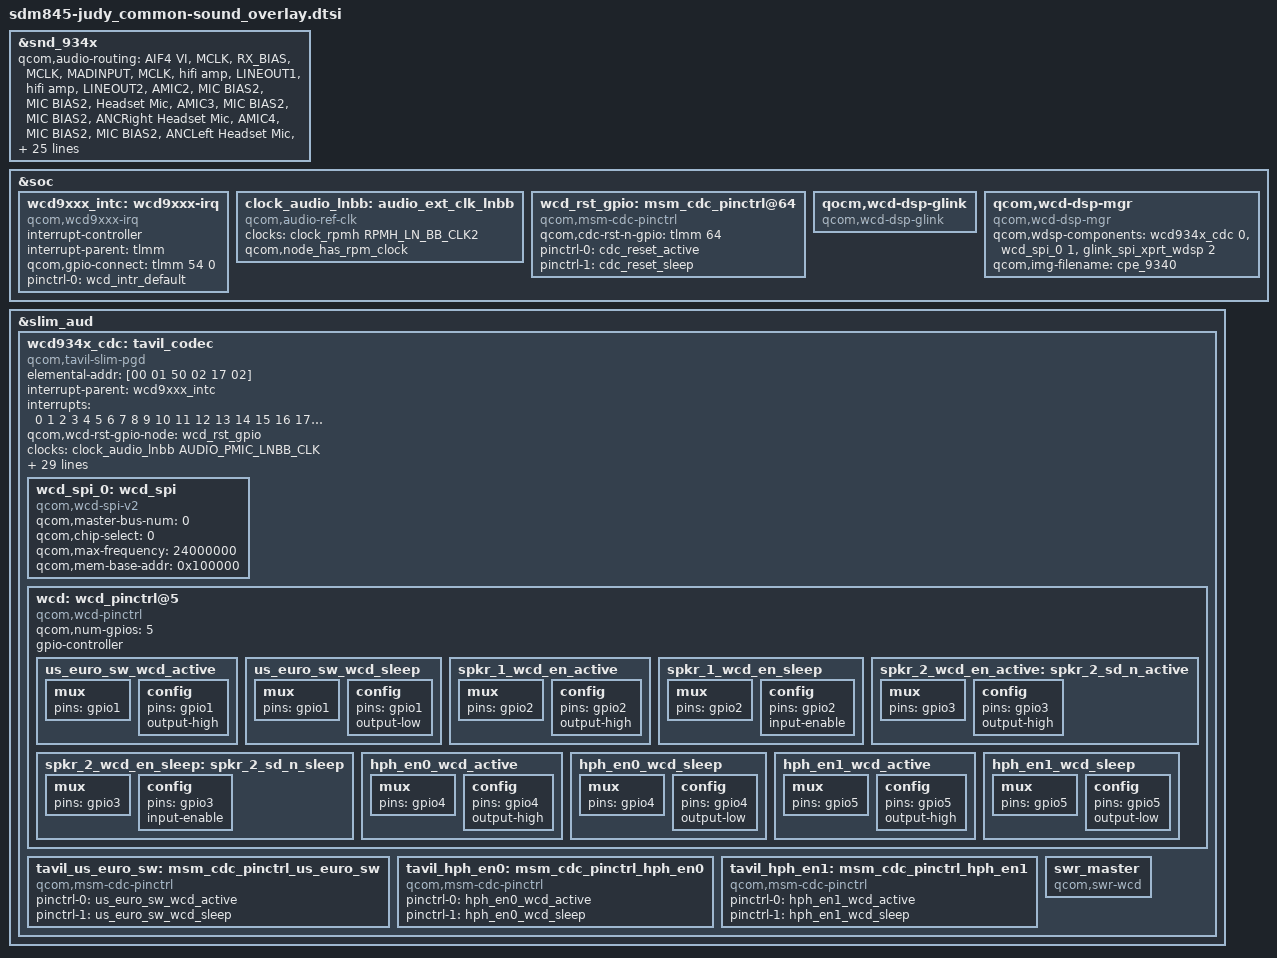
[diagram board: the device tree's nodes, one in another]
/* Copyright (c) 2017, The Linux Foundation. All rights reserved.
 *
 * This program is free software; you can redistribute it and/or modify
 * it under the terms of the GNU General Public License version 2 and
 * only version 2 as published by the Free Software Foundation.
 *
 * This program is distributed in the hope that it will be useful,
 * but WITHOUT ANY WARRANTY; without even the implied warranty of
 * MERCHANTABILITY or FITNESS FOR A PARTICULAR PURPOSE.  See the
 * GNU General Public License for more details.
 */

#include <dt-bindings/clock/qcom,audio-ext-clk.h>

&snd_934x {
	qcom,audio-routing =
		"AIF4 VI", "MCLK",
		"RX_BIAS", "MCLK",
		"MADINPUT", "MCLK",
		"hifi amp", "LINEOUT1",
		"hifi amp", "LINEOUT2",
		"AMIC2", "MIC BIAS2",
		"MIC BIAS2", "Headset Mic",
		"AMIC3", "MIC BIAS2",
		"MIC BIAS2", "ANCRight Headset Mic",
		"AMIC4", "MIC BIAS2",
		"MIC BIAS2", "ANCLeft Headset Mic",
		"AMIC5", "MIC BIAS3",
		"MIC BIAS3", "Handset Mic",
		"DMIC0", "MIC BIAS1",
		"MIC BIAS1", "Digital Mic0",
		"DMIC1", "MIC BIAS1",
		"MIC BIAS1", "Digital Mic1",
		"DMIC2", "MIC BIAS3",
		"MIC BIAS3", "Digital Mic2",
		"DMIC3", "MIC BIAS3",
		"MIC BIAS3", "Digital Mic3",
		"DMIC4", "MIC BIAS4",
		"MIC BIAS4", "Digital Mic4",
		"DMIC5", "MIC BIAS4",
		"MIC BIAS4", "Digital Mic5",
		"SpkrLeft IN", "SPK1 OUT",
		"SpkrRight IN", "SPK2 OUT";

	qcom,msm-mbhc-hphl-swh = <1>;
	qcom,msm-mbhc-gnd-swh = <1>;
	qcom,msm-mbhc-hs-mic-max-threshold-mv = <1700>;
	qcom,msm-mbhc-hs-mic-min-threshold-mv = <50>;
	qcom,hph-en0-gpio = <&tavil_hph_en0>;
	qcom,hph-en1-gpio = <&tavil_hph_en1>;
	qcom,tavil-mclk-clk-freq = <9600000>;

	asoc-codec = <&stub_codec>;
	asoc-codec-names = "msm-stub-codec.1";

	pinctrl-names = "aud_active", "aud_sleep";
	pinctrl-0 = <&wcd_usbc_analog_en2_active>;
	pinctrl-1 = <&wcd_usbc_analog_en2_idle>;

	qcom,wsa-max-devs = <2>;
	qcom,wsa-devs = <&wsa881x_0211>, <&wsa881x_0212>,
			<&wsa881x_0213>, <&wsa881x_0214>;
	qcom,wsa-aux-dev-prefix = "SpkrLeft", "SpkrRight",
				  "SpkrLeft", "SpkrRight";
};

&soc {
/*	wcd_usbc_analog_en1_gpio: msm_cdc_pinctrl@49 {
		compatible = "qcom,msm-cdc-pinctrl";
		pinctrl-names = "aud_active", "aud_sleep";
		pinctrl-0 = <&wcd_usbc_analog_en1_active>;
		pinctrl-1 = <&wcd_usbc_analog_en1_idle>;
	};
*/
	wcd9xxx_intc: wcd9xxx-irq {
		status = "ok";
		compatible = "qcom,wcd9xxx-irq";
		interrupt-controller;
		#interrupt-cells = <1>;
		interrupt-parent = <&tlmm>;
		qcom,gpio-connect = <&tlmm 54 0>;
		pinctrl-names = "default";
		pinctrl-0 = <&wcd_intr_default>;
	};

	clock_audio_lnbb: audio_ext_clk_lnbb {
		status = "ok";
		compatible = "qcom,audio-ref-clk";
		clock-names = "osr_clk";
		clocks = <&clock_rpmh RPMH_LN_BB_CLK2>;
		qcom,node_has_rpm_clock;
		#clock-cells = <1>;
	};

	wcd_rst_gpio: msm_cdc_pinctrl@64 {
		compatible = "qcom,msm-cdc-pinctrl";
		qcom,cdc-rst-n-gpio = <&tlmm 64 0>;
		pinctrl-names = "aud_active", "aud_sleep";
		pinctrl-0 = <&cdc_reset_active>;
		pinctrl-1 = <&cdc_reset_sleep>;
	};

	qocm,wcd-dsp-glink {
		compatible = "qcom,wcd-dsp-glink";
	};

	qcom,wcd-dsp-mgr {
		compatible = "qcom,wcd-dsp-mgr";
		qcom,wdsp-components = <&wcd934x_cdc 0>,
				       <&wcd_spi_0 1>,
				       <&glink_spi_xprt_wdsp 2>;
		qcom,img-filename = "cpe_9340";
	};
};

&slim_aud {
	wcd934x_cdc: tavil_codec {
		compatible = "qcom,tavil-slim-pgd";
		elemental-addr = [00 01 50 02 17 02];

		interrupt-parent = <&wcd9xxx_intc>;
		interrupts = <0 1 2 3 4 5 6 7 8 9 10 11 12 13 14 15 16
			      17 18 19 20 21 22 23 24 25 26 27 28 29
			      30 31>;

		qcom,wcd-rst-gpio-node = <&wcd_rst_gpio>;

		clock-names = "wcd_clk";
		clocks = <&clock_audio_lnbb AUDIO_PMIC_LNBB_CLK>;

		cdc-vdd-buck-supply = <&pm8998_s4>;
		qcom,cdc-vdd-buck-voltage = <1800000 1800000>;
		qcom,cdc-vdd-buck-current = <650000>;

		cdc-buck-sido-supply = <&pm8998_s4>;
		qcom,cdc-buck-sido-voltage = <1800000 1800000>;
		qcom,cdc-buck-sido-current = <250000>;

		cdc-vdd-tx-h-supply = <&pm8998_s4>;
		qcom,cdc-vdd-tx-h-voltage = <1800000 1800000>;
		qcom,cdc-vdd-tx-h-current = <25000>;

		cdc-vdd-rx-h-supply = <&pm8998_s4>;
		qcom,cdc-vdd-rx-h-voltage = <1800000 1800000>;
		qcom,cdc-vdd-rx-h-current = <25000>;

		cdc-vddpx-1-supply = <&pm8998_s4>;
		qcom,cdc-vddpx-1-voltage = <1800000 1800000>;
		qcom,cdc-vddpx-1-current = <10000>;

		qcom,cdc-static-supplies = "cdc-vdd-buck",
					   "cdc-buck-sido",
					   "cdc-vdd-tx-h",
					   "cdc-vdd-rx-h",
					   "cdc-vddpx-1";

		qcom,cdc-micbias1-mv = <1800>;
		qcom,cdc-micbias2-mv = <2100>;
		qcom,cdc-micbias3-mv = <1800>;
		qcom,cdc-micbias4-mv = <1800>;

		qcom,cdc-mclk-clk-rate = <9600000>;
		qcom,cdc-slim-ifd = "tavil-slim-ifd";
		qcom,cdc-slim-ifd-elemental-addr = [00 00 50 02 17 02];
		qcom,cdc-dmic-sample-rate = <4800000>;
		qcom,cdc-mad-dmic-rate = <600000>;

		qcom,wdsp-cmpnt-dev-name = "tavil_codec";

		wcd_spi_0: wcd_spi {
			compatible = "qcom,wcd-spi-v2";
			qcom,master-bus-num = <0>;
			qcom,chip-select = <0>;
			qcom,max-frequency = <24000000>;
			qcom,mem-base-addr = <0x100000>;
		};

	};
};

&slim_aud {
	tavil_codec {
		wcd: wcd_pinctrl@5 {
			compatible = "qcom,wcd-pinctrl";
			qcom,num-gpios = <5>;
			gpio-controller;
			#gpio-cells = <2>;

			us_euro_sw_wcd_active: us_euro_sw_wcd_active {
				mux {
					pins = "gpio1";
				};

				config {
					pins = "gpio1";
					output-high;
				};
			};

			us_euro_sw_wcd_sleep: us_euro_sw_wcd_sleep {
				mux {
					pins = "gpio1";
				};

				config {
					pins = "gpio1";
					output-low;
				};
			};

			spkr_1_wcd_en_active: spkr_1_wcd_en_active {
				mux {
					pins = "gpio2";
				};

				config {
					pins = "gpio2";
					output-high;
				};
			};

			spkr_1_wcd_en_sleep: spkr_1_wcd_en_sleep {
				mux {
					pins = "gpio2";
				};

				config {
					pins = "gpio2";
					input-enable;
				};
			};

			spkr_2_wcd_en_active: spkr_2_sd_n_active {
				mux {
					pins = "gpio3";
				};

				config {
					pins = "gpio3";
					output-high;
				};
			};

			spkr_2_wcd_en_sleep: spkr_2_sd_n_sleep {
				mux {
					pins = "gpio3";
				};

				config {
					pins = "gpio3";
					input-enable;
				};
			};

			hph_en0_wcd_active: hph_en0_wcd_active {
				mux {
					pins = "gpio4";
				};

				config {
					pins = "gpio4";
					output-high;
				};
			};

			hph_en0_wcd_sleep: hph_en0_wcd_sleep {
				mux {
					pins = "gpio4";
				};

				config {
					pins = "gpio4";
					output-low;
				};
			};

			hph_en1_wcd_active: hph_en1_wcd_active {
				mux {
					pins = "gpio5";
				};

				config {
					pins = "gpio5";
					output-high;
				};
			};

			hph_en1_wcd_sleep: hph_en1_wcd_sleep {
				mux {
					pins = "gpio5";
				};

				config {
					pins = "gpio5";
					output-low;
				};
			};
		};

/*		wsa_spkr_wcd_sd1: msm_cdc_pinctrll {
		      compatible = "qcom,msm-cdc-pinctrl";
		      pinctrl-names = "aud_active", "aud_sleep";
		      pinctrl-0 = <&spkr_1_wcd_en_active>;
		      pinctrl-1 = <&spkr_1_wcd_en_sleep>;
		};

		wsa_spkr_wcd_sd2: msm_cdc_pinctrlr {
		      compatible = "qcom,msm-cdc-pinctrl";
		      pinctrl-names = "aud_active", "aud_sleep";
		      pinctrl-0 = <&spkr_2_wcd_en_active>;
		      pinctrl-1 = <&spkr_2_wcd_en_sleep>;
		};
*/
		tavil_us_euro_sw: msm_cdc_pinctrl_us_euro_sw {
		      compatible = "qcom,msm-cdc-pinctrl";
		      pinctrl-names = "aud_active", "aud_sleep";
		      pinctrl-0 = <&us_euro_sw_wcd_active>;
		      pinctrl-1 = <&us_euro_sw_wcd_sleep>;
		};

		tavil_hph_en0: msm_cdc_pinctrl_hph_en0 {
		      compatible = "qcom,msm-cdc-pinctrl";
		      pinctrl-names = "aud_active", "aud_sleep";
		      pinctrl-0 = <&hph_en0_wcd_active>;
		      pinctrl-1 = <&hph_en0_wcd_sleep>;
		};

		tavil_hph_en1: msm_cdc_pinctrl_hph_en1 {
		      compatible = "qcom,msm-cdc-pinctrl";
		      pinctrl-names = "aud_active", "aud_sleep";
		      pinctrl-0 = <&hph_en1_wcd_active>;
		      pinctrl-1 = <&hph_en1_wcd_sleep>;
		};

		swr_master {
			compatible = "qcom,swr-wcd";
			#address-cells = <2>;
			#size-cells = <0>;

		/*	wsa881x_0211: wsa881x@20170211 {
				compatible = "qcom,wsa881x";
				reg = <0x00 0x20170211>;
				qcom,spkr-sd-n-node = <&wsa_spkr_wcd_sd1>;
			};

			wsa881x_0212: wsa881x@20170212 {
				compatible = "qcom,wsa881x";
				reg = <0x00 0x20170212>;
				qcom,spkr-sd-n-node = <&wsa_spkr_wcd_sd2>;
			};

			wsa881x_0213: wsa881x@21170213 {
				compatible = "qcom,wsa881x";
				reg = <0x00 0x21170213>;
				qcom,spkr-sd-n-node = <&wsa_spkr_wcd_sd1>;
			};

			wsa881x_0214: wsa881x@21170214 {
				compatible = "qcom,wsa881x";
				reg = <0x00 0x21170214>;
				qcom,spkr-sd-n-node = <&wsa_spkr_wcd_sd2>;
			};
		*/
		};
	};
};
